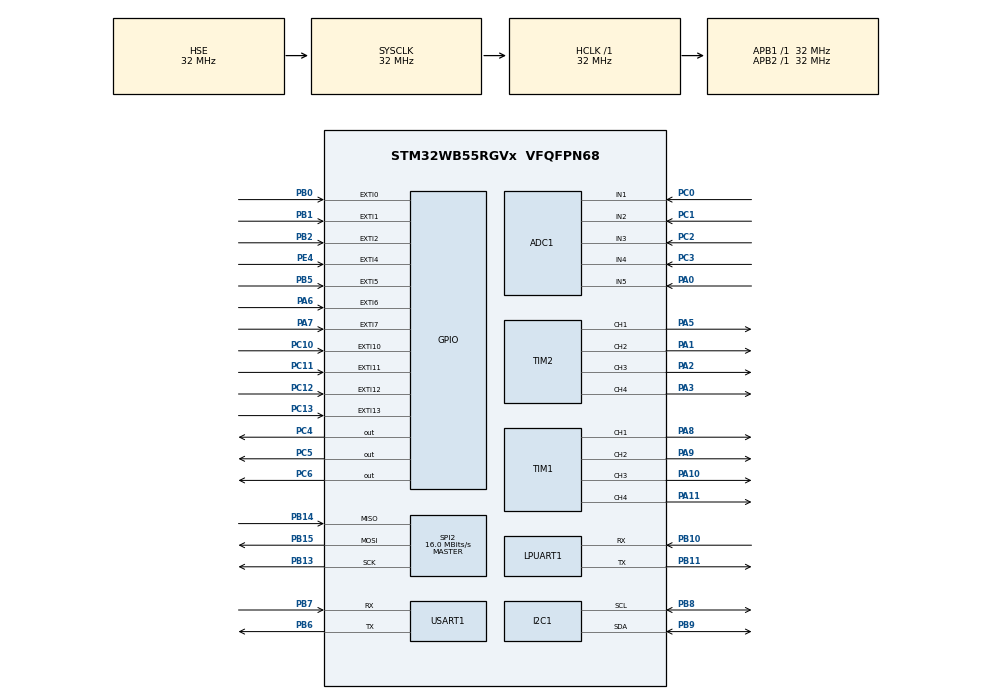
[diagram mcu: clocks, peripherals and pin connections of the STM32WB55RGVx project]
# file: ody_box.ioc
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ADC1.Channel-0\#ChannelRegularConversion=ADC_CHANNEL_1
ADC1.NbrOfConversionFlag=1
ADC1.OffsetNumber-0\#ChannelRegularConversion=ADC_OFFSET_NONE
ADC1.Rank-0\#ChannelRegularConversion=1
ADC1.SamplingTime-0\#ChannelRegularConversion=ADC_SAMPLETIME_2CYCLES_5
ADC1.master=1
I2C1.Timing=0x00707CBB
Mcu.Family=STM32WB
Mcu.Name=STM32WB55RGVx
Mcu.Package=VFQFPN68
NVIC.PriorityGroup=NVIC_PRIORITYGROUP_4
OSC_IN.Mode=HSE-External-Oscillator
OSC_IN.Signal=RCC_OSC_IN
OSC_OUT.Mode=HSE-External-Oscillator
OSC_OUT.Signal=RCC_OSC_OUT
PA0.Signal=ADCx_IN5
PA1.Signal=S_TIM2_CH2
PA10.Signal=S_TIM1_CH3
PA11.Signal=S_TIM1_CH4
PA13.Mode=JTAG_5_pins
PA13.Signal=SYS_JTMS-SWDIO
PA14.Mode=JTAG_5_pins
PA14.Signal=SYS_JTCK-SWCLK
PA15.Mode=JTAG_5_pins
PA15.Signal=SYS_JTDI
PA2.Signal=S_TIM2_CH3
PA3.Signal=S_TIM2_CH4
PA5.Signal=S_TIM2_CH1
PA6.Signal=GPXTI6
PA7.Signal=GPXTI7
PA8.Signal=S_TIM1_CH1
PA9.Signal=S_TIM1_CH2
PB0.Signal=GPXTI0
PB1.Signal=GPXTI1
PB10.Mode=Asynchronous
PB10.Signal=LPUART1_RX
PB11.Mode=Asynchronous
PB11.Signal=LPUART1_TX
PB13.Mode=Full_Duplex_Master
PB13.Signal=SPI2_SCK
PB14.Mode=Full_Duplex_Master
PB14.Signal=SPI2_MISO
PB15.Mode=Full_Duplex_Master
PB15.Signal=SPI2_MOSI
PB2.Signal=GPXTI2
PB3.Mode=JTAG_5_pins
PB3.Signal=SYS_JTDO-SWO
PB4.Mode=JTAG_5_pins
PB4.Signal=SYS_JTRST
PB5.Signal=GPXTI5
PB6.Mode=Asynchronous
PB6.Signal=USART1_TX
PB7.Mode=Asynchronous
PB7.Signal=USART1_RX
PB8.Mode=I2C
PB8.Signal=I2C1_SCL
PB9.Mode=I2C
PB9.Signal=I2C1_SDA
PC0.Signal=ADCx_IN1
PC1.Signal=ADCx_IN2
PC10.Signal=GPXTI10
PC11.Signal=GPXTI11
PC12.Signal=GPXTI12
PC13.Signal=GPXTI13
PC14-OSC32_IN.Mode=LSE-External-Oscillator
PC14-OSC32_IN.Signal=RCC_OSC32_IN
PC15-OSC32_OUT.Mode=LSE-External-Oscillator
PC15-OSC32_OUT.Signal=RCC_OSC32_OUT
PC2.Signal=ADCx_IN3
PC3.Signal=ADCx_IN4
PC4.Signal=GPIO_Output
PC5.Signal=GPIO_Output
PC6.Signal=GPIO_Output
PE4.Signal=GPXTI4
ProjectManager.HeapSize=0x200
ProjectManager.StackSize=0x400
ProjectManager.TargetToolchain=SW4STM32
RCC.ADCFreq_Value=48000000
RCC.AHBFreq_Value=32000000
RCC.APB1Freq_Value=32000000
RCC.APB1TimFreq_Value=32000000
RCC.APB2Freq_Value=32000000
RCC.APB2TimFreq_Value=32000000
RCC.APB3Freq_Value=16000000
RCC.CortexFreq_Value=32000000
RCC.HCLKFreq_Value=32000000
RCC.HSE_VALUE=32000000
RCC.HSI48_VALUE=48000000
RCC.HSI_VALUE=16000000
RCC.MSIClockRange=RCC_MSIRANGE_10
RCC.PLLM=RCC_PLLM_DIV2
RCC.PLLSAI1N=6
RCC.RFWKPClockSelection=RCC_RFWKPCLKSOURCE_LSE
RCC.RTCClockSelection=RCC_RTCCLKSOURCE_LSE
RCC.SYSCLKFreq_VALUE=32000000
RCC.SYSCLKSource=RCC_SYSCLKSOURCE_HSE
RCC.USBFreq_Value=48000000
RCC.VCOOutputFreq_Value=128000000
RF1.Mode=RF1_Activate
RF1.Signal=RF_RF1
SH.ADCx_IN1.0=ADC1_IN1,IN1-Single-Ended
SH.ADCx_IN2.0=ADC1_IN2,IN2-Single-Ended
SH.ADCx_IN3.0=ADC1_IN3,IN3-Single-Ended
SH.ADCx_IN4.0=ADC1_IN4,IN4-Single-Ended
SH.ADCx_IN5.0=ADC1_IN5,IN5-Single-Ended
SH.S_TIM1_CH1.0=TIM1_CH1,PWM Generation1 CH1
SH.S_TIM1_CH2.0=TIM1_CH2,PWM Generation2 CH2
SH.S_TIM1_CH3.0=TIM1_CH3,PWM Generation3 CH3
SH.S_TIM1_CH4.0=TIM1_CH4,PWM Generation4 CH4
SH.S_TIM2_CH1.0=TIM2_CH1,PWM Generation1 CH1
SH.S_TIM2_CH2.0=TIM2_CH2,Output Compare2 CH2
SH.S_TIM2_CH3.0=TIM2_CH3,Output Compare3 CH3
SH.S_TIM2_CH4.0=TIM2_CH4,Output Compare4 CH4
SPI2.CalculateBaudRate=16.0 MBits/s
SPI2.Direction=SPI_DIRECTION_2LINES
SPI2.Mode=SPI_MODE_MASTER
SPI2.VirtualType=VM_MASTER
STM32_WPAN.BLE_APPLICATION_TYPE=BLE_SERVER_PROFILE
STM32_WPAN.CFG_FAST_CONN_ADV_INTERVAL_MAX_HEXA=0xa0
STM32_WPAN.CFG_LP_CONN_ADV_INTERVAL_MAX_HEXA=0xfa0
TIM1.Channel-PWM\ Generation1\ CH1=TIM_CHANNEL_1
TIM1.Channel-PWM\ Generation2\ CH2=TIM_CHANNEL_2
TIM1.Channel-PWM\ Generation3\ CH3=TIM_CHANNEL_3
TIM1.Channel-PWM\ Generation4\ CH4=TIM_CHANNEL_4
TIM2.Channel-Output\ Compare2\ CH2=TIM_CHANNEL_2
TIM2.Channel-Output\ Compare3\ CH3=TIM_CHANNEL_3
TIM2.Channel-Output\ Compare4\ CH4=TIM_CHANNEL_4
TIM2.Channel-PWM\ Generation1\ CH1=TIM_CHANNEL_1
USART1.VirtualMode-Asynchronous=VM_ASYNC
VP_HSEM_VS_HSEM.Mode=HSEM_Activate
VP_RTC_VS_RTC_Activate.Mode=RTC_Enabled
VP_STM32_WPAN_VS_BLE_HOST.Mode=STM32_WPAN_Enabled
VP_TIM16_VS_ClockSourceINT.Mode=Enable_Timer
VP_TIM17_VS_ClockSourceINT.Mode=Enable_Timer
board=custom

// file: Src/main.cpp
/* USER CODE BEGIN Header */
/**
  ******************************************************************************
  * @file           : main.c
  * @brief          : Main program body
  ******************************************************************************
  * @attention
  *
  * <h2><center>&copy; Copyright (c) 2019 STMicroelectronics.
  * All rights reserved.</center></h2>
  *
  * This software component is licensed by ST under BSD 3-Clause license,
  * the "License"; You may not use this file except in compliance with the
  * License. You may obtain a copy of the License at:
  *                        opensource.org/licenses/BSD-3-Clause
  *
  ******************************************************************************
  */
/* USER CODE END Header */

#define __DEBUG__

#ifdef __DEBUG__
#pragma message("DEBUG MODE ACTIVATED")
#endif
#ifndef __DEBUG__
#pragma message("RELEASE MODE ACTIVATED")
#endif

#include "main.h"
#include "app_entry.h"
#include "Box.hpp"
#include "scheduler.h"

ADC_HandleTypeDef hadc1;

I2C_HandleTypeDef hi2c1;

UART_HandleTypeDef hlpuart1;
UART_HandleTypeDef huart1;

RTC_HandleTypeDef hrtc;

SPI_HandleTypeDef hspi2;

TIM_HandleTypeDef htim1;
TIM_HandleTypeDef htim2;
TIM_HandleTypeDef htim16;
TIM_HandleTypeDef htim17;

void SystemClock_Config(void);
static void MX_GPIO_Init(void);
static void MX_ADC1_Init(void);
static void MX_I2C1_Init(void);
static void MX_LPUART1_UART_Init(void);
static void MX_USART1_UART_Init(void);
static void MX_RF_Init(void);
static void MX_SPI2_Init(void);
static void MX_TIM1_Init(void);
static void MX_TIM2_Init(void);
static void MX_TIM16_Init(void);
static void MX_TIM17_Init(void);
static void MX_RTC_Init(void);

int main(void)
{

  /* MCU Configuration--------------------------------------------------------*/

  /* Reset of all peripherals, Initializes the Flash interface and the Systick. */
  HAL_Init();

  /* Configure the system clock */
  SystemClock_Config();

  /* Initialize all configured peripherals */
  MX_GPIO_Init();
  MX_ADC1_Init();
  MX_I2C1_Init();
  MX_LPUART1_UART_Init();
  MX_USART1_UART_Init();
  MX_RF_Init();
  MX_SPI2_Init();
  MX_TIM1_Init();
  MX_TIM2_Init();
  MX_TIM16_Init();
  MX_TIM17_Init();
  MX_RTC_Init();
  /* USER CODE BEGIN 2 */

  Box::Instance()->setHandlers(&hspi2,&htim1);
  Box::Instance()->Setup();

  /* USER CODE END 2 */
  APPE_Init();

#ifdef __DEBUG__
  Box::Instance()->Test();
#endif

  /* Infinite loop */
  while (1)
  {

    /* USER CODE BEGIN 3 */

#ifndef __DEBUG__
	  Box::Instance()->Loop();
#endif
	  HAL_Delay(50);

	  SCH_Run(~0);

  }
  /* USER CODE END 3 */
}

void SystemClock_Config(void)
{
  RCC_OscInitTypeDef RCC_OscInitStruct = {0};
  RCC_ClkInitTypeDef RCC_ClkInitStruct = {0};
  RCC_PeriphCLKInitTypeDef PeriphClkInitStruct = {0};

  /** Macro to configure the PLL multiplication factor
  */
  __HAL_RCC_PLL_PLLM_CONFIG(RCC_PLLM_DIV2);
  /** Macro to configure the PLL clock source
  */
  __HAL_RCC_PLL_PLLSOURCE_CONFIG(RCC_PLLSOURCE_MSI);
  /** Configure LSE Drive Capability
  */
  __HAL_RCC_LSEDRIVE_CONFIG(RCC_LSEDRIVE_LOW);
  /** Configure the main internal regulator output voltage
  */
  __HAL_PWR_VOLTAGESCALING_CONFIG(PWR_REGULATOR_VOLTAGE_SCALE1);
  /** Initializes the CPU, AHB and APB busses clocks
  */
  RCC_OscInitStruct.OscillatorType = RCC_OSCILLATORTYPE_HSI|RCC_OSCILLATORTYPE_HSE
                              |RCC_OSCILLATORTYPE_LSE|RCC_OSCILLATORTYPE_MSI;
  RCC_OscInitStruct.HSEState = RCC_HSE_ON;
  RCC_OscInitStruct.LSEState = RCC_LSE_ON;
  RCC_OscInitStruct.HSIState = RCC_HSI_ON;
  RCC_OscInitStruct.MSIState = RCC_MSI_ON;
  RCC_OscInitStruct.HSICalibrationValue = RCC_HSICALIBRATION_DEFAULT;
  RCC_OscInitStruct.MSICalibrationValue = RCC_MSICALIBRATION_DEFAULT;
  RCC_OscInitStruct.MSIClockRange = RCC_MSIRANGE_10;
  RCC_OscInitStruct.PLL.PLLState = RCC_PLL_NONE;
  if (HAL_RCC_OscConfig(&RCC_OscInitStruct) != HAL_OK)
  {
    Error_Handler();
  }
  /** Configure the SYSCLKSource, HCLK, PCLK1 and PCLK2 clocks dividers
  */
  RCC_ClkInitStruct.ClockType = RCC_CLOCKTYPE_HCLK4|RCC_CLOCKTYPE_HCLK2
                              |RCC_CLOCKTYPE_HCLK|RCC_CLOCKTYPE_SYSCLK
                              |RCC_CLOCKTYPE_PCLK1|RCC_CLOCKTYPE_PCLK2;
  RCC_ClkInitStruct.SYSCLKSource = RCC_SYSCLKSOURCE_HSE;
  RCC_ClkInitStruct.AHBCLKDivider = RCC_SYSCLK_DIV1;
  RCC_ClkInitStruct.APB1CLKDivider = RCC_HCLK_DIV1;
  RCC_ClkInitStruct.APB2CLKDivider = RCC_HCLK_DIV1;
  RCC_ClkInitStruct.AHBCLK2Divider = RCC_SYSCLK_DIV1;
  RCC_ClkInitStruct.AHBCLK4Divider = RCC_SYSCLK_DIV1;

  if (HAL_RCC_ClockConfig(&RCC_ClkInitStruct, FLASH_LATENCY_1) != HAL_OK)
  {
    Error_Handler();
  }
  /** Initializes the peripherals clocks
  */
  PeriphClkInitStruct.PeriphClockSelection = RCC_PERIPHCLK_SMPS|RCC_PERIPHCLK_RFWAKEUP
                              |RCC_PERIPHCLK_RTC|RCC_PERIPHCLK_USART1
                              |RCC_PERIPHCLK_LPUART1|RCC_PERIPHCLK_I2C1
                              |RCC_PERIPHCLK_ADC;
  PeriphClkInitStruct.PLLSAI1.PLLN = 6;
  PeriphClkInitStruct.PLLSAI1.PLLP = RCC_PLLP_DIV2;
  PeriphClkInitStruct.PLLSAI1.PLLQ = RCC_PLLQ_DIV2;
  PeriphClkInitStruct.PLLSAI1.PLLR = RCC_PLLR_DIV2;
  PeriphClkInitStruct.PLLSAI1.PLLSAI1ClockOut = RCC_PLLSAI1_ADCCLK;
  PeriphClkInitStruct.Usart1ClockSelection = RCC_USART1CLKSOURCE_PCLK2;
  PeriphClkInitStruct.Lpuart1ClockSelection = RCC_LPUART1CLKSOURCE_PCLK1;
  PeriphClkInitStruct.I2c1ClockSelection = RCC_I2C1CLKSOURCE_PCLK1;
  PeriphClkInitStruct.AdcClockSelection = RCC_ADCCLKSOURCE_PLLSAI1;
  PeriphClkInitStruct.RTCClockSelection = RCC_RTCCLKSOURCE_LSE;
  PeriphClkInitStruct.RFWakeUpClockSelection = RCC_RFWKPCLKSOURCE_LSE;
  PeriphClkInitStruct.SmpsClockSelection = RCC_SMPSCLKSOURCE_HSE;
  PeriphClkInitStruct.SmpsDivSelection = RCC_SMPSCLKDIV_RANGE0;

  if (HAL_RCCEx_PeriphCLKConfig(&PeriphClkInitStruct) != HAL_OK)
  {
    Error_Handler();
  }
}

static void MX_ADC1_Init(void)
{

  ADC_ChannelConfTypeDef sConfig = {0};

  /** Common config
  */
  hadc1.Instance = ADC1;
  hadc1.Init.ClockPrescaler = ADC_CLOCK_ASYNC_DIV1;
  hadc1.Init.Resolution = ADC_RESOLUTION_12B;
  hadc1.Init.DataAlign = ADC_DATAALIGN_RIGHT;
  hadc1.Init.ScanConvMode = ADC_SCAN_DISABLE;
  hadc1.Init.EOCSelection = ADC_EOC_SINGLE_CONV;
  hadc1.Init.LowPowerAutoWait = DISABLE;
  hadc1.Init.ContinuousConvMode = DISABLE;
  hadc1.Init.NbrOfConversion = 1;
  hadc1.Init.DiscontinuousConvMode = DISABLE;
  hadc1.Init.ExternalTrigConv = ADC_SOFTWARE_START;
  hadc1.Init.ExternalTrigConvEdge = ADC_EXTERNALTRIGCONVEDGE_NONE;
  hadc1.Init.DMAContinuousRequests = DISABLE;
  hadc1.Init.Overrun = ADC_OVR_DATA_PRESERVED;
  hadc1.Init.OversamplingMode = DISABLE;
  if (HAL_ADC_Init(&hadc1) != HAL_OK)
  {
    Error_Handler();
  }
  /** Configure Regular Channel
  */
  sConfig.Channel = ADC_CHANNEL_1;
  sConfig.Rank = ADC_REGULAR_RANK_1;
  sConfig.SamplingTime = ADC_SAMPLETIME_2CYCLES_5;
  sConfig.SingleDiff = ADC_SINGLE_ENDED;
  sConfig.OffsetNumber = ADC_OFFSET_NONE;
  sConfig.Offset = 0;
  if (HAL_ADC_ConfigChannel(&hadc1, &sConfig) != HAL_OK)
  {
    Error_Handler();
  }

}

static void MX_I2C1_Init(void)
{

  hi2c1.Instance = I2C1;
  hi2c1.Init.Timing = 0x00707CBB;
  hi2c1.Init.OwnAddress1 = 0;
  hi2c1.Init.AddressingMode = I2C_ADDRESSINGMODE_7BIT;
  hi2c1.Init.DualAddressMode = I2C_DUALADDRESS_DISABLE;
  hi2c1.Init.OwnAddress2 = 0;
  hi2c1.Init.OwnAddress2Masks = I2C_OA2_NOMASK;
  hi2c1.Init.GeneralCallMode = I2C_GENERALCALL_DISABLE;
  hi2c1.Init.NoStretchMode = I2C_NOSTRETCH_DISABLE;
  if (HAL_I2C_Init(&hi2c1) != HAL_OK)
  {
    Error_Handler();
  }
  /** Configure Analogue filter
  */
  if (HAL_I2CEx_ConfigAnalogFilter(&hi2c1, I2C_ANALOGFILTER_ENABLE) != HAL_OK)
  {
    Error_Handler();
  }
  /** Configure Digital filter
  */
  if (HAL_I2CEx_ConfigDigitalFilter(&hi2c1, 0) != HAL_OK)
  {
    Error_Handler();
  }

}

static void MX_LPUART1_UART_Init(void)
{

  hlpuart1.Instance = LPUART1;
  hlpuart1.Init.BaudRate = 209700;
  hlpuart1.Init.WordLength = UART_WORDLENGTH_7B;
  hlpuart1.Init.StopBits = UART_STOPBITS_1;
  hlpuart1.Init.Parity = UART_PARITY_NONE;
  hlpuart1.Init.Mode = UART_MODE_TX_RX;
  hlpuart1.Init.HwFlowCtl = UART_HWCONTROL_NONE;
  hlpuart1.Init.OneBitSampling = UART_ONE_BIT_SAMPLE_DISABLE;
  hlpuart1.Init.ClockPrescaler = UART_PRESCALER_DIV1;
  hlpuart1.AdvancedInit.AdvFeatureInit = UART_ADVFEATURE_NO_INIT;
  hlpuart1.FifoMode = UART_FIFOMODE_DISABLE;
  if (HAL_UART_Init(&hlpuart1) != HAL_OK)
  {
    Error_Handler();
  }
  if (HAL_UARTEx_SetTxFifoThreshold(&hlpuart1, UART_TXFIFO_THRESHOLD_1_8) != HAL_OK)
  {
    Error_Handler();
  }
  if (HAL_UARTEx_SetRxFifoThreshold(&hlpuart1, UART_RXFIFO_THRESHOLD_1_8) != HAL_OK)
  {
    Error_Handler();
  }
  if (HAL_UARTEx_DisableFifoMode(&hlpuart1) != HAL_OK)
  {
    Error_Handler();
  }

}

static void MX_USART1_UART_Init(void)
{

  huart1.Instance = USART1;
  huart1.Init.BaudRate = 115200;
  huart1.Init.WordLength = UART_WORDLENGTH_7B;
  huart1.Init.StopBits = UART_STOPBITS_1;
  huart1.Init.Parity = UART_PARITY_NONE;
  huart1.Init.Mode = UART_MODE_TX_RX;
  huart1.Init.HwFlowCtl = UART_HWCONTROL_NONE;
  huart1.Init.OverSampling = UART_OVERSAMPLING_16;
  huart1.Init.OneBitSampling = UART_ONE_BIT_SAMPLE_DISABLE;
  huart1.Init.ClockPrescaler = UART_PRESCALER_DIV1;
  huart1.AdvancedInit.AdvFeatureInit = UART_ADVFEATURE_NO_INIT;
  if (HAL_UART_Init(&huart1) != HAL_OK)
  {
    Error_Handler();
  }
  if (HAL_UARTEx_SetTxFifoThreshold(&huart1, UART_TXFIFO_THRESHOLD_1_8) != HAL_OK)
  {
    Error_Handler();
  }
  if (HAL_UARTEx_SetRxFifoThreshold(&huart1, UART_RXFIFO_THRESHOLD_1_8) != HAL_OK)
  {
    Error_Handler();
  }
  if (HAL_UARTEx_DisableFifoMode(&huart1) != HAL_OK)
  {
    Error_Handler();
  }

}

static void MX_RF_Init(void)
{

}

static void MX_RTC_Init(void)
{

  /** Initialize RTC Only
  */
  hrtc.Instance = RTC;
  hrtc.Init.HourFormat = RTC_HOURFORMAT_24;
  hrtc.Init.AsynchPrediv = 127;
  hrtc.Init.SynchPrediv = 255;
  hrtc.Init.OutPut = RTC_OUTPUT_DISABLE;
  hrtc.Init.OutPutRemap = RTC_OUTPUT_REMAP_NONE;
  hrtc.Init.OutPutPolarity = RTC_OUTPUT_POLARITY_HIGH;
  hrtc.Init.OutPutType = RTC_OUTPUT_TYPE_OPENDRAIN;
  if (HAL_RTC_Init(&hrtc) != HAL_OK)
  {
    Error_Handler();
  }

}

static void MX_SPI2_Init(void)
{

  /* SPI2 parameter configuration*/
  hspi2.Instance = SPI2;
  hspi2.Init.Mode = SPI_MODE_MASTER;
  hspi2.Init.Direction = SPI_DIRECTION_2LINES;
  hspi2.Init.DataSize = SPI_DATASIZE_4BIT;
  hspi2.Init.CLKPolarity = SPI_POLARITY_LOW;
  hspi2.Init.CLKPhase = SPI_PHASE_1EDGE;
  hspi2.Init.NSS = SPI_NSS_SOFT;
  hspi2.Init.BaudRatePrescaler = SPI_BAUDRATEPRESCALER_2;
  hspi2.Init.FirstBit = SPI_FIRSTBIT_MSB;
  hspi2.Init.TIMode = SPI_TIMODE_DISABLE;
  hspi2.Init.CRCCalculation = SPI_CRCCALCULATION_DISABLE;
  hspi2.Init.CRCPolynomial = 7;
  hspi2.Init.CRCLength = SPI_CRC_LENGTH_DATASIZE;
  hspi2.Init.NSSPMode = SPI_NSS_PULSE_ENABLE;
  if (HAL_SPI_Init(&hspi2) != HAL_OK)
  {
    Error_Handler();
  }

}

static void MX_TIM1_Init(void)
{

  TIM_MasterConfigTypeDef sMasterConfig = {0};
  TIM_OC_InitTypeDef sConfigOC = {0};
  TIM_BreakDeadTimeConfigTypeDef sBreakDeadTimeConfig = {0};

  htim1.Instance = TIM1;
  htim1.Init.Prescaler = 0;
  htim1.Init.CounterMode = TIM_COUNTERMODE_UP;
  htim1.Init.Period = 0;
  htim1.Init.ClockDivision = TIM_CLOCKDIVISION_DIV1;
  htim1.Init.RepetitionCounter = 0;
  htim1.Init.AutoReloadPreload = TIM_AUTORELOAD_PRELOAD_DISABLE;
  if (HAL_TIM_PWM_Init(&htim1) != HAL_OK)
  {
    Error_Handler();
  }
  sMasterConfig.MasterOutputTrigger = TIM_TRGO_RESET;
  sMasterConfig.MasterOutputTrigger2 = TIM_TRGO2_RESET;
  sMasterConfig.MasterSlaveMode = TIM_MASTERSLAVEMODE_DISABLE;
  if (HAL_TIMEx_MasterConfigSynchronization(&htim1, &sMasterConfig) != HAL_OK)
  {
    Error_Handler();
  }
  sConfigOC.OCMode = TIM_OCMODE_PWM1;
  sConfigOC.Pulse = 0;
  sConfigOC.OCPolarity = TIM_OCPOLARITY_HIGH;
  sConfigOC.OCNPolarity = TIM_OCNPOLARITY_HIGH;
  sConfigOC.OCFastMode = TIM_OCFAST_DISABLE;
  sConfigOC.OCIdleState = TIM_OCIDLESTATE_RESET;
  sConfigOC.OCNIdleState = TIM_OCNIDLESTATE_RESET;
  if (HAL_TIM_PWM_ConfigChannel(&htim1, &sConfigOC, TIM_CHANNEL_1) != HAL_OK)
  {
    Error_Handler();
  }
  if (HAL_TIM_PWM_ConfigChannel(&htim1, &sConfigOC, TIM_CHANNEL_2) != HAL_OK)
  {
    Error_Handler();
  }
  if (HAL_TIM_PWM_ConfigChannel(&htim1, &sConfigOC, TIM_CHANNEL_3) != HAL_OK)
  {
    Error_Handler();
  }
  if (HAL_TIM_PWM_ConfigChannel(&htim1, &sConfigOC, TIM_CHANNEL_4) != HAL_OK)
  {
    Error_Handler();
  }
  sBreakDeadTimeConfig.OffStateRunMode = TIM_OSSR_DISABLE;
  sBreakDeadTimeConfig.OffStateIDLEMode = TIM_OSSI_DISABLE;
  sBreakDeadTimeConfig.LockLevel = TIM_LOCKLEVEL_OFF;
  sBreakDeadTimeConfig.DeadTime = 0;
  sBreakDeadTimeConfig.BreakState = TIM_BREAK_DISABLE;
  sBreakDeadTimeConfig.BreakPolarity = TIM_BREAKPOLARITY_HIGH;
  sBreakDeadTimeConfig.BreakFilter = 0;
  sBreakDeadTimeConfig.Break2State = TIM_BREAK2_DISABLE;
  sBreakDeadTimeConfig.Break2Polarity = TIM_BREAK2POLARITY_HIGH;
  sBreakDeadTimeConfig.Break2Filter = 0;
  sBreakDeadTimeConfig.AutomaticOutput = TIM_AUTOMATICOUTPUT_DISABLE;
  if (HAL_TIMEx_ConfigBreakDeadTime(&htim1, &sBreakDeadTimeConfig) != HAL_OK)
  {
    Error_Handler();
  }
  HAL_TIM_MspPostInit(&htim1);

}

static void MX_TIM2_Init(void)
{

  TIM_MasterConfigTypeDef sMasterConfig = {0};
  TIM_OC_InitTypeDef sConfigOC = {0};

  htim2.Instance = TIM2;
  htim2.Init.Prescaler = 0;
  htim2.Init.CounterMode = TIM_COUNTERMODE_UP;
  htim2.Init.Period = 0;
  htim2.Init.ClockDivision = TIM_CLOCKDIVISION_DIV1;
  htim2.Init.AutoReloadPreload = TIM_AUTORELOAD_PRELOAD_DISABLE;
  if (HAL_TIM_PWM_Init(&htim2) != HAL_OK)
  {
    Error_Handler();
  }
  if (HAL_TIM_OC_Init(&htim2) != HAL_OK)
  {
    Error_Handler();
  }
  sMasterConfig.MasterOutputTrigger = TIM_TRGO_RESET;
  sMasterConfig.MasterSlaveMode = TIM_MASTERSLAVEMODE_DISABLE;
  if (HAL_TIMEx_MasterConfigSynchronization(&htim2, &sMasterConfig) != HAL_OK)
  {
    Error_Handler();
  }
  sConfigOC.OCMode = TIM_OCMODE_PWM1;
  sConfigOC.Pulse = 0;
  sConfigOC.OCPolarity = TIM_OCPOLARITY_HIGH;
  sConfigOC.OCFastMode = TIM_OCFAST_DISABLE;
  if (HAL_TIM_PWM_ConfigChannel(&htim2, &sConfigOC, TIM_CHANNEL_1) != HAL_OK)
  {
    Error_Handler();
  }
  sConfigOC.OCMode = TIM_OCMODE_TIMING;
  if (HAL_TIM_OC_ConfigChannel(&htim2, &sConfigOC, TIM_CHANNEL_2) != HAL_OK)
  {
    Error_Handler();
  }
  if (HAL_TIM_OC_ConfigChannel(&htim2, &sConfigOC, TIM_CHANNEL_3) != HAL_OK)
  {
    Error_Handler();
  }
  if (HAL_TIM_OC_ConfigChannel(&htim2, &sConfigOC, TIM_CHANNEL_4) != HAL_OK)
  {
    Error_Handler();
  }
  HAL_TIM_MspPostInit(&htim2);

}

static void MX_TIM16_Init(void)
{

  htim16.Instance = TIM16;
  htim16.Init.Prescaler = 0;
  htim16.Init.CounterMode = TIM_COUNTERMODE_UP;
  htim16.Init.Period = 0;
  htim16.Init.ClockDivision = TIM_CLOCKDIVISION_DIV1;
  htim16.Init.RepetitionCounter = 0;
  htim16.Init.AutoReloadPreload = TIM_AUTORELOAD_PRELOAD_DISABLE;
  if (HAL_TIM_Base_Init(&htim16) != HAL_OK)
  {
    Error_Handler();
  }

}

static void MX_TIM17_Init(void)
{

  htim17.Instance = TIM17;
  htim17.Init.Prescaler = 0;
  htim17.Init.CounterMode = TIM_COUNTERMODE_UP;
  htim17.Init.Period = 0;
  htim17.Init.ClockDivision = TIM_CLOCKDIVISION_DIV1;
  htim17.Init.RepetitionCounter = 0;
  htim17.Init.AutoReloadPreload = TIM_AUTORELOAD_PRELOAD_DISABLE;
  if (HAL_TIM_Base_Init(&htim17) != HAL_OK)
  {
    Error_Handler();
  }

}

static void MX_GPIO_Init(void)
{
  GPIO_InitTypeDef GPIO_InitStruct = {0};

  /* GPIO Ports Clock Enable */
  __HAL_RCC_GPIOC_CLK_ENABLE();
  __HAL_RCC_GPIOB_CLK_ENABLE();
  __HAL_RCC_GPIOA_CLK_ENABLE();
  __HAL_RCC_GPIOE_CLK_ENABLE();

  /*Configure GPIO pin Output Level */
  HAL_GPIO_WritePin(GPIOC, GPIO_PIN_4|GPIO_PIN_5|GPIO_PIN_6, GPIO_PIN_RESET);

  /*Configure GPIO pins : PC13 PC10 PC11 PC12 */
  GPIO_InitStruct.Pin = GPIO_PIN_13|GPIO_PIN_10|GPIO_PIN_11|GPIO_PIN_12;
  GPIO_InitStruct.Mode = GPIO_MODE_IT_RISING;
  GPIO_InitStruct.Pull = GPIO_NOPULL;
  HAL_GPIO_Init(GPIOC, &GPIO_InitStruct);

  /*Configure GPIO pins : PA6 PA7 */
  GPIO_InitStruct.Pin = GPIO_PIN_6|GPIO_PIN_7;
  GPIO_InitStruct.Mode = GPIO_MODE_IT_RISING;
  GPIO_InitStruct.Pull = GPIO_NOPULL;
  HAL_GPIO_Init(GPIOA, &GPIO_InitStruct);

  /*Configure GPIO pins : PC4 PC5 PC6 */
  GPIO_InitStruct.Pin = GPIO_PIN_4|GPIO_PIN_5|GPIO_PIN_6;
  GPIO_InitStruct.Mode = GPIO_MODE_OUTPUT_PP;
  GPIO_InitStruct.Pull = GPIO_NOPULL;
  GPIO_InitStruct.Speed = GPIO_SPEED_FREQ_LOW;
  HAL_GPIO_Init(GPIOC, &GPIO_InitStruct);

  /*Configure GPIO pins : PB2 PB0 PB1 PB5 */
  GPIO_InitStruct.Pin = GPIO_PIN_2|GPIO_PIN_0|GPIO_PIN_1|GPIO_PIN_5;
  GPIO_InitStruct.Mode = GPIO_MODE_IT_RISING;
  GPIO_InitStruct.Pull = GPIO_NOPULL;
  HAL_GPIO_Init(GPIOB, &GPIO_InitStruct);

  /*Configure GPIO pin : PE4 */
  GPIO_InitStruct.Pin = GPIO_PIN_4;
  GPIO_InitStruct.Mode = GPIO_MODE_IT_RISING;
  GPIO_InitStruct.Pull = GPIO_NOPULL;
  HAL_GPIO_Init(GPIOE, &GPIO_InitStruct);

}

void Error_Handler(void)
{
}

/************************ (C) COPYRIGHT STMicroelectronics *****END OF FILE****/
